# STM32L021xx register map
File version: 1.0
Registers are 32-bit, read-write, reset 0x0 unless marked. A register's access mark holds for its fields unless they carry their own. Offsets are from the block's base; lines under a group give offsets from that group; [hi:lo] are bit positions; {n}, {i} and the like mark numbered series; 'fields as' and 'values as' point back to an identical list; <NAME> marks a mode.

## Memory map
0x1FF80000 OB — Option Bytes Registers
0x40000000 TIM2 — TIM
0x40002800 RTC — Real-Time Clock
0x40002C00 WWDG — Window WATCHDOG
0x40003000 IWDG — Independent WATCHDOG
0x40004400 USART2 — Universal Synchronous Asynchronous Receiver Transmitter
0x40004800 LPUART1 — Universal Synchronous Asynchronous Receiver Transmitter
0x40005400 I2C1 — Inter-integrated Circuit Interface
0x40007000 PWR — Power Control
0x40007C00 LPTIM1 — LPTIMIMER
0x40010000 SYSCFG — SysTem Configuration
0x40010018 COMP1 — Comparator
0x40010018 COMP12_COMMON
0x4001001C COMP2 — Comparator
0x40010400 EXTI — External Interrupt/Event Controller
0x40010800 TIM21 — TIM
0x40012400 ADC1 — Analog to Digital Converter
0x40013000 SPI1 — Serial Peripheral Interface
0x40015800 DBGMCU — Debug MCU
0x40020000 DMA1
0x40021000 RCC — Reset and Clock Control
0x40022000 FLASH — FLASH Registers
0x40023000 CRC — CRC calculation unit
0x40026000 AES — AES hardware accelerator
0x50000000 GPIOA — General Purpose IO
0x50000400 GPIOB — General Purpose IO
0x50000800 GPIOC — General Purpose IO

## Interrupts
0 WWDG — Window WatchDog Interrupt
2 RTC — RTC through EXTI Line Interrupt
3 FLASH — FLASH Interrupt
4 RCC — RCC Interrupt
5 EXTI0_1 (EXTI) — EXTI Line 0 and 1 Interrupts
6 EXTI2_3 (EXTI) — EXTI Line 2 and 3 Interrupts
7 EXTI4_15 (EXTI) — EXTI Line 4 to 15 Interrupts
9 DMA1_Channel1 (DMA1) — DMA1 Channel 1 Interrupt
10 DMA1_Channel2_3 (DMA1) — DMA1 Channel 2 and Channel 3 Interrupts
11 DMA1_Channel4_5 (DMA1) — DMA1 Channel 4 and Channel 5 Interrupts
12 ADC1_COMP (ADC1) — ADC1, COMP1 and COMP2 Interrupts
13 LPTIM1 — LPTIM1 Interrupt
15 TIM2 — TIM2 Interrupt
20 TIM21 — TIM21 Interrupt
23 I2C1 — I2C1 Interrupt
25 SPI1 — SPI1 Interrupt
28 USART2 — USART2 Interrupt
29 AES_LPUART1 (LPUART1, AES) — AES and LPUART1 Interrupts

## OB — Option Bytes Registers
Base 0x1FF80000
0x00 RDP — Read protection register
0x04 USER
0x08 WRP01 — write protection Bytes 0 and 1

## WWDG — Window WATCHDOG
Base 0x40002C00
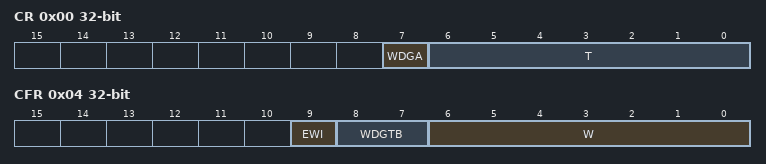
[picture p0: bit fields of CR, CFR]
0x00 CR — WWDG Control register
  [7] WDGA — Activation bit
  [6:0] T — T[6:0] bits (7-Bit counter (MSB to LSB))
0x04 CFR — WWDG Configuration register
  [9] EWI — Early Wakeup Interrupt
  [8:7] WDGTB — WDGTB[1:0] bits (Timer Base)
    0=PRESCALER_1 (WWDG counter clock = (PCLK1/4096)/1); 1=PRESCALER_2 (WWDG counter clock = (PCLK1/4096)/2); 2=PRESCALER_4 (WWDG counter clock = (PCLK1/4096)/4); 3=PRESCALER_8 (WWDG counter clock = (PCLK1/4096)/8)
  [6:0] W — W[6:0] bits (7-bit window value)
0x08 SR — WWDG Status register
  [0] EWIF — Early Wakeup Interrupt Flag

## IWDG — Independent WATCHDOG
Base 0x40003000
0x00 KR — IWDG Key register
  [15:0] KEY — Key value (write only, read 0000h)
0x04 PR — IWDG Prescaler register
  [2:0] PR — PR[2:0] (Prescaler divider)
0x08 RLR — IWDG Reload register
  [11:0] RL — Watchdog counter reload value
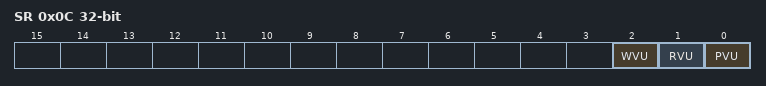
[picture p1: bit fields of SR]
0x0C SR — IWDG Status register
  [2] WVU — Watchdog counter window value update
  [1] RVU — Watchdog counter reload value update
  [0] PVU — Watchdog prescaler value update
0x10 WINR — IWDG Window register
  [11:0] WIN — Watchdog counter window value

## PWR — Power Control
Base 0x40007000
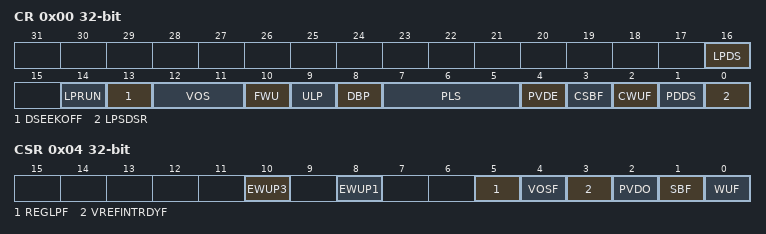
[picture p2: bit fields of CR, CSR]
0x00 CR — PWR power control register
  [16] LPDS — regulator in low power deepsleep mode
    0=MAIN (Voltage regulator in main mode during deepsleep mode when PWR_CR_LPSDSR = 0); 1=LOW_POWER (Voltage regulator in low-power mode during deepsleep mode when PWR_CR_LPSDSR = 0)
  [14] LPRUN — Low power run mode
  [13] DSEEKOFF — Deep Sleep mode with EEPROM kept Off
  [12:11] VOS — VOS[1:0] bits (Voltage scaling range selection)
    1=SCALE1 (1.8V (range 1)); 2=SCALE2 (1.5V (range 2)); 3=SCALE3 (1.2V (range 3))
  [10] FWU — Fast wakeup
  [9] ULP — Ultra Low Power mode
  [8] DBP — Disable Backup Domain write protection
  [7:5] PLS — PLS[2:0] bits (PVD Level Selection)
    0=PVDLEVEL_0 (Voltage threshold detected by PVD 1.9 V); 1=PVDLEVEL_1 (Voltage threshold detected by PVD 2.1 V); 2=PVDLEVEL_2 (Voltage threshold detected by PVD 2.3 V); 3=PVDLEVEL_3 (Voltage threshold detected by PVD 2.5 V); 4=PVDLEVEL_4 (Voltage threshold detected by PVD 2.7 V); 5=PVDLEVEL_5 (Voltage threshold detected by PVD 2.9 V); 6=PVDLEVEL_6 (Voltage threshold detected by PVD 3.1 V); 7=PVDLEVEL_7 (External input analog voltage (Compare internally to VREFINT))
  [4] PVDE — Power Voltage Detector Enable
  [3] CSBF — Clear Standby Flag
  [2] CWUF — Clear Wakeup Flag
  [1] PDDS — Power Down Deepsleep
    0=STOP (Enter Stop mode when the CPU enters deepsleep); 1=STANDBY (Enter Standby mode when the CPU enters deepsleep)
  [0] LPSDSR — Low-power deepsleep/sleep/low power run
    0=MAIN (Voltage regulator in main mode during deepsleep/sleep/low-power run mode); 1=LOW_POWER (Voltage regulator in low-power mode during deepsleep/sleep/low-power run mode)
0x04 CSR — PWR power control/status register
  [10] EWUP3 — Enable WKUP pin 3
  [8] EWUP1 — Enable WKUP pin 1
  [5] REGLPF — Regulator LP flag
  [4] VOSF — Voltage Scaling select flag
  [3] VREFINTRDYF — Internal voltage reference (VREFINT) ready flag
  [2] PVDO — PVD Output
  [1] SBF — Standby Flag
  [0] WUF — Wakeup Flag
